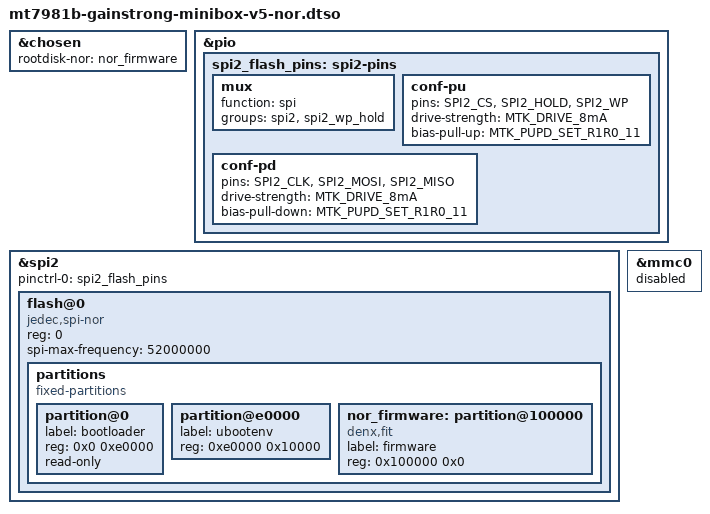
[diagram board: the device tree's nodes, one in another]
/* SPDX-License-Identifier: (GPL-2.0-only OR MIT) */
/dts-v1/;
/plugin/;

#include <dt-bindings/pinctrl/mt65xx.h>

&chosen {
	rootdisk-nor = <&nor_firmware>;
};

&pio {
	spi2_flash_pins: spi2-pins {
		mux {
			function = "spi";
			groups = "spi2", "spi2_wp_hold";
		};

		conf-pu {
			pins = "SPI2_CS", "SPI2_HOLD", "SPI2_WP";
			drive-strength = <MTK_DRIVE_8mA>;
			bias-pull-up = <MTK_PUPD_SET_R1R0_11>;
		};

		conf-pd {
			pins = "SPI2_CLK", "SPI2_MOSI", "SPI2_MISO";
			drive-strength = <MTK_DRIVE_8mA>;
			bias-pull-down = <MTK_PUPD_SET_R1R0_11>;
		};
	};
};

&spi2 {
	#address-cells = <1>;
	#size-cells = <0>;
	pinctrl-names = "default";
	pinctrl-0 = <&spi2_flash_pins>;
	status = "okay";

	flash@0 {
		compatible = "jedec,spi-nor";
		reg = <0>;
		spi-max-frequency = <52000000>;

		partitions {
			compatible = "fixed-partitions";
			#address-cells = <1>;
			#size-cells = <1>;

			partition@0 {
				label = "bootloader";
				reg = <0x0 0xe0000>;
				read-only;
			};

			partition@e0000 {
				label = "ubootenv";
				reg = <0xe0000 0x10000>;
			};

			/* 0xf0000-0x100000 is intentionally left unused. */
			nor_firmware: partition@100000 {
				compatible = "denx,fit";
				label = "firmware";
				reg = <0x100000 0x0>;
			};
		};
	};
};

&mmc0 {
	status = "disabled";
};
